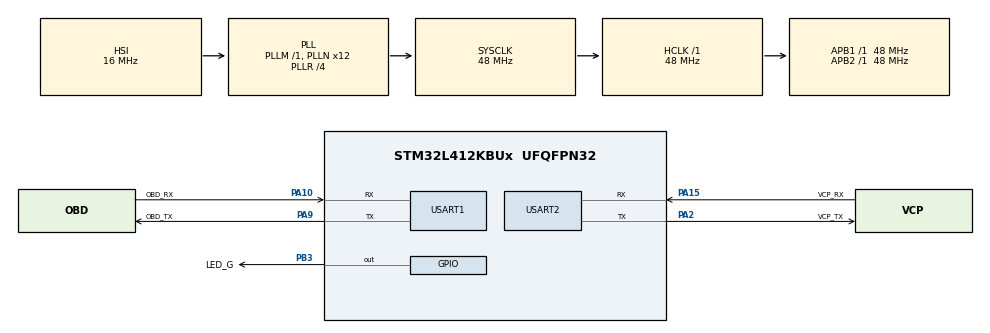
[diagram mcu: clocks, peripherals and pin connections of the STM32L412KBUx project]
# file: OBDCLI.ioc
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Dma.Request0=USART1_RX
Dma.Request1=USART1_TX
Dma.Request2=USART2_RX
Dma.Request3=USART2_TX
Dma.USART1_RX.0.Direction=DMA_PERIPH_TO_MEMORY
Dma.USART1_RX.0.Instance=DMA1_Channel5
Dma.USART1_RX.0.MemDataAlignment=DMA_MDATAALIGN_BYTE
Dma.USART1_RX.0.MemInc=DMA_MINC_ENABLE
Dma.USART1_RX.0.Mode=DMA_NORMAL
Dma.USART1_RX.0.PeriphDataAlignment=DMA_PDATAALIGN_BYTE
Dma.USART1_RX.0.PeriphInc=DMA_PINC_DISABLE
Dma.USART1_RX.0.Priority=DMA_PRIORITY_LOW
Dma.USART1_TX.1.Direction=DMA_MEMORY_TO_PERIPH
Dma.USART1_TX.1.Instance=DMA1_Channel4
Dma.USART1_TX.1.MemDataAlignment=DMA_MDATAALIGN_BYTE
Dma.USART1_TX.1.MemInc=DMA_MINC_ENABLE
Dma.USART1_TX.1.Mode=DMA_NORMAL
Dma.USART1_TX.1.PeriphDataAlignment=DMA_PDATAALIGN_BYTE
Dma.USART1_TX.1.PeriphInc=DMA_PINC_DISABLE
Dma.USART1_TX.1.Priority=DMA_PRIORITY_LOW
Dma.USART2_RX.2.Direction=DMA_PERIPH_TO_MEMORY
Dma.USART2_RX.2.Instance=DMA1_Channel6
Dma.USART2_RX.2.MemDataAlignment=DMA_MDATAALIGN_BYTE
Dma.USART2_RX.2.MemInc=DMA_MINC_ENABLE
Dma.USART2_RX.2.Mode=DMA_NORMAL
Dma.USART2_RX.2.PeriphDataAlignment=DMA_PDATAALIGN_BYTE
Dma.USART2_RX.2.PeriphInc=DMA_PINC_DISABLE
Dma.USART2_RX.2.Priority=DMA_PRIORITY_LOW
Dma.USART2_TX.3.Direction=DMA_MEMORY_TO_PERIPH
Dma.USART2_TX.3.Instance=DMA1_Channel7
Dma.USART2_TX.3.MemDataAlignment=DMA_MDATAALIGN_BYTE
Dma.USART2_TX.3.MemInc=DMA_MINC_ENABLE
Dma.USART2_TX.3.Mode=DMA_NORMAL
Dma.USART2_TX.3.PeriphDataAlignment=DMA_PDATAALIGN_BYTE
Dma.USART2_TX.3.PeriphInc=DMA_PINC_DISABLE
Dma.USART2_TX.3.Priority=DMA_PRIORITY_LOW
Mcu.Family=STM32L4
Mcu.Name=STM32L412KBUx
Mcu.Package=UFQFPN32
NVIC.DMA1_Channel4_IRQn=true\:0\:0\:false\:false\:true\:false\:true\:true
NVIC.DMA1_Channel5_IRQn=true\:0\:0\:false\:false\:true\:false\:true\:true
NVIC.DMA1_Channel6_IRQn=true\:0\:0\:false\:false\:true\:false\:true\:true
NVIC.DMA1_Channel7_IRQn=true\:0\:0\:false\:false\:true\:false\:true\:true
NVIC.PriorityGroup=NVIC_PRIORITYGROUP_4
NVIC.USART1_IRQn=true\:0\:0\:false\:false\:true\:true\:true\:true
NVIC.USART2_IRQn=true\:0\:0\:false\:false\:true\:true\:true\:true
PA10.GPIO_Label=OBD_RX
PA10.Mode=Asynchronous
PA10.Signal=USART1_RX
PA13\ (JTMS/SWDIO).GPIO_Label=SWDIO
PA13\ (JTMS/SWDIO).Mode=Serial_Wire
PA13\ (JTMS/SWDIO).Signal=SYS_JTMS-SWDIO
PA14\ (JTCK/SWCLK).GPIO_Label=SWCLK
PA14\ (JTCK/SWCLK).Mode=Serial_Wire
PA14\ (JTCK/SWCLK).Signal=SYS_JTCK-SWCLK
PA15\ (JTDI).GPIO_Label=VCP_RX
PA15\ (JTDI).Mode=Asynchronous
PA15\ (JTDI).Signal=USART2_RX
PA2.GPIO_Label=VCP_TX
PA2.Mode=Asynchronous
PA2.Signal=USART2_TX
PA9.GPIO_Label=OBD_TX
PA9.Mode=Asynchronous
PA9.Signal=USART1_TX
PB3\ (JTDO/TRACESWO).GPIO_Label=LED_G
PB3\ (JTDO/TRACESWO).Signal=GPIO_Output
PC14-OSC32_IN\ (PC14).Mode=LSE-External-Oscillator
PC14-OSC32_IN\ (PC14).Signal=RCC_OSC32_IN
PC15-OSC32_OUT\ (PC15).Mode=LSE-External-Oscillator
PC15-OSC32_OUT\ (PC15).Signal=RCC_OSC32_OUT
ProjectManager.HeapSize=0x200
ProjectManager.StackSize=0x400
ProjectManager.TargetToolchain=STM32CubeIDE
RCC.ADCFreq_Value=48000000
RCC.AHBFreq_Value=48000000
RCC.APB1Freq_Value=48000000
RCC.APB1TimFreq_Value=48000000
RCC.APB2Freq_Value=48000000
RCC.APB2TimFreq_Value=48000000
RCC.CortexFreq_Value=48000000
RCC.FLatency=FLASH_LATENCY_2
RCC.HCLKFreq_Value=48000000
RCC.HSE_VALUE=24000000
RCC.HSI48_VALUE=48000000
RCC.HSICalibrationValue=64
RCC.HSI_VALUE=16000000
RCC.MSIClockRange=RCC_MSIRANGE_11
RCC.MSI_VALUE=48000000
RCC.PLLN=12
RCC.PLLR=RCC_PLLR_DIV4
RCC.PLLSourceVirtual=RCC_PLLSOURCE_HSI
RCC.RTCClockSelection=RCC_RTCCLKSOURCE_LSE
RCC.SYSCLKFreq_VALUE=48000000
RCC.SYSCLKSource=RCC_SYSCLKSOURCE_PLLCLK
RCC.USBFreq_Value=48000000
RCC.VCOOutputFreq_Value=192000000
USART1.VirtualMode-Asynchronous=VM_ASYNC
USART2.VirtualMode-Asynchronous=VM_ASYNC
VP_RTC_VS_RTC_Activate.Mode=RTC_Enabled
board=NUCLEO-L412KB

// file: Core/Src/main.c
/* USER CODE BEGIN Header */
/**
  ******************************************************************************
  * @file           : main.c
  * @brief          : Main program body
  ******************************************************************************
  * @attention
  *
  * Copyright (c) 2025 STMicroelectronics.
  * All rights reserved.
  *
  * This software is licensed under terms that can be found in the LICENSE file
  * in the root directory of this software component.
  * If no LICENSE file comes with this software, it is provided AS-IS.
  *
  ******************************************************************************
  */
/* USER CODE END Header */
#include "main.h"
#include "dma.h"
#include "rtc.h"
#include "usart.h"
#include "gpio.h"

/* USER CODE BEGIN Includes */
#include "cli.h"
#include "obd.h"

/* USER CODE END Includes */

/* USER CODE BEGIN PD */
#define BLINK_PERIOD_MS 150U

/* USER CODE END PD */

void SystemClock_Config(void);

int main(void)
{

  /* MCU Configuration--------------------------------------------------------*/

  /* Reset of all peripherals, Initializes the Flash interface and the Systick. */
  HAL_Init();

  /* Configure the system clock */
  SystemClock_Config();

  /* Initialize all configured peripherals */
  MX_GPIO_Init();
  MX_DMA_Init();
  MX_USART2_UART_Init();
  MX_RTC_Init();
  MX_USART1_UART_Init();
  /* USER CODE BEGIN 2 */

  if (obd_init(&huart1, &huart2) != OBD_OK) {
    Error_Handler();
  }

  if (cli_init(&huart1, &huart2) != CLI_OK) {
    Error_Handler();
  }

  /* USER CODE END 2 */

  /* Infinite loop */
  /* USER CODE BEGIN WHILE */
  while (1)
  {
    HAL_GPIO_WritePin(LED_G_GPIO_Port, LED_G_Pin, GPIO_PIN_SET);
	  HAL_Delay(BLINK_PERIOD_MS);
	  HAL_GPIO_WritePin(LED_G_GPIO_Port, LED_G_Pin, GPIO_PIN_RESET);
	  HAL_Delay(BLINK_PERIOD_MS);

    /* USER CODE END WHILE */

  }
}

void SystemClock_Config(void)
{
  RCC_OscInitTypeDef RCC_OscInitStruct = {0};
  RCC_ClkInitTypeDef RCC_ClkInitStruct = {0};

  /** Configure the main internal regulator output voltage
  */
  if (HAL_PWREx_ControlVoltageScaling(PWR_REGULATOR_VOLTAGE_SCALE1) != HAL_OK)
  {
    Error_Handler();
  }

  /** Configure LSE Drive Capability
  */
  HAL_PWR_EnableBkUpAccess();
  __HAL_RCC_LSEDRIVE_CONFIG(RCC_LSEDRIVE_LOW);

  /** Initializes the RCC Oscillators according to the specified parameters
  * in the RCC_OscInitTypeDef structure.
  */
  RCC_OscInitStruct.OscillatorType = RCC_OSCILLATORTYPE_HSI|RCC_OSCILLATORTYPE_LSE;
  RCC_OscInitStruct.LSEState = RCC_LSE_ON;
  RCC_OscInitStruct.HSIState = RCC_HSI_ON;
  RCC_OscInitStruct.HSICalibrationValue = RCC_HSICALIBRATION_DEFAULT;
  RCC_OscInitStruct.PLL.PLLState = RCC_PLL_ON;
  RCC_OscInitStruct.PLL.PLLSource = RCC_PLLSOURCE_HSI;
  RCC_OscInitStruct.PLL.PLLM = 1;
  RCC_OscInitStruct.PLL.PLLN = 12;
  RCC_OscInitStruct.PLL.PLLQ = RCC_PLLQ_DIV2;
  RCC_OscInitStruct.PLL.PLLR = RCC_PLLR_DIV4;
  if (HAL_RCC_OscConfig(&RCC_OscInitStruct) != HAL_OK)
  {
    Error_Handler();
  }

  /** Initializes the CPU, AHB and APB buses clocks
  */
  RCC_ClkInitStruct.ClockType = RCC_CLOCKTYPE_HCLK|RCC_CLOCKTYPE_SYSCLK
                              |RCC_CLOCKTYPE_PCLK1|RCC_CLOCKTYPE_PCLK2;
  RCC_ClkInitStruct.SYSCLKSource = RCC_SYSCLKSOURCE_PLLCLK;
  RCC_ClkInitStruct.AHBCLKDivider = RCC_SYSCLK_DIV1;
  RCC_ClkInitStruct.APB1CLKDivider = RCC_HCLK_DIV1;
  RCC_ClkInitStruct.APB2CLKDivider = RCC_HCLK_DIV1;

  if (HAL_RCC_ClockConfig(&RCC_ClkInitStruct, FLASH_LATENCY_2) != HAL_OK)
  {
    Error_Handler();
  }
}

void Error_Handler(void)
{
  __disable_irq();
  while (1)
  {
  }
}
